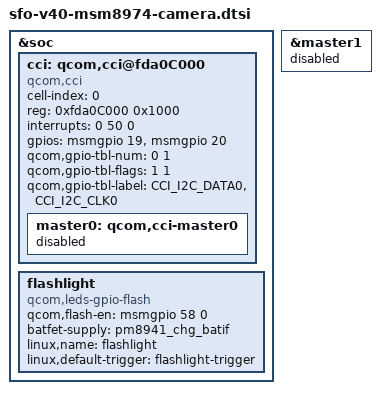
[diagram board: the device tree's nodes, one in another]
/*
 * Copyright (c) 2012-2013, The Linux Foundation. All rights reserved.
 *
 * This program is free software; you can redistribute it and/or modify
 * it under the terms of the GNU General Public License version 2 and
 * only version 2 as published by the Free Software Foundation.
 *
 * This program is distributed in the hope that it will be useful,
 * but WITHOUT ANY WARRANTY; without even the implied warranty of
 * MERCHANTABILITY or FITNESS FOR A PARTICULAR PURPOSE.  See the
 * GNU General Public License for more details.
 */

&soc {
	cci: qcom,cci@fda0C000 {
		cell-index = <0>;
		compatible = "qcom,cci";
		reg = <0xfda0C000 0x1000>;
		#address-cells = <1>;
		#size-cells = <0>;
		reg-names = "cci";
		interrupts = <0 50 0>;
		interrupt-names = "cci";
		gpios = <&msmgpio 19 0>,
			<&msmgpio 20 0>;
		qcom,gpio-tbl-num = <0 1>;
		qcom,gpio-tbl-flags = <1 1>;
		qcom,gpio-tbl-label = "CCI_I2C_DATA0",
				      "CCI_I2C_CLK0";
		master0: qcom,cci-master0 {
			status = "disabled";
		};
	};

  	flashlight {
                compatible = "qcom,leds-gpio-flash";
                status = "okay";
                qcom,flash-en = <&msmgpio 58 0>;
                batfet-supply = <&pm8941_chg_batif>;
                linux,name = "flashlight";
                linux,default-trigger = "flashlight-trigger";
        };
};
&master1 {
	status = "disabled";
};

